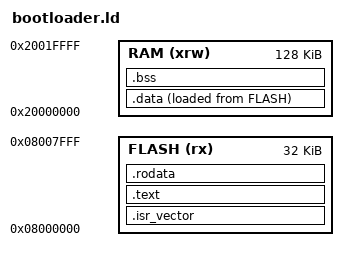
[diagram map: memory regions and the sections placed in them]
/* ============================================================================
 * Linker Script for STM32F446ZET6 Bootloader (BigTreeTech Octopus)
 * Sector 0 & 1: 32 KB (0x08000000 - 0x08007FFF)
 * ============================================================================ */

ENTRY(Reset_Handler)

_estack = ORIGIN(RAM) + LENGTH(RAM); /* 0x20020000 */

MEMORY
{
    FLASH (rx)  : ORIGIN = 0x08000000, LENGTH = 32K
    RAM   (xrw) : ORIGIN = 0x20000000, LENGTH = 128K
}

SECTIONS
{
    .isr_vector :
    {
        . = ALIGN(4);
        KEEP(*(.isr_vector))
        . = ALIGN(4);
    } > FLASH

    .text :
    {
        . = ALIGN(4);
        *(.text)
        *(.text*)
        *(.glue_7)
        *(.glue_7t)
        *(.eh_frame)
        . = ALIGN(4);
        _etext = .;
    } > FLASH

    .rodata :
    {
        . = ALIGN(4);
        *(.rodata)
        *(.rodata*)
        . = ALIGN(4);
    } > FLASH

    _sidata = LOADADDR(.data);

    .data :
    {
        . = ALIGN(4);
        _sdata = .;
        *(.data)
        *(.data*)
        . = ALIGN(4);
        _edata = .;
    } > RAM AT> FLASH

    .bss :
    {
        . = ALIGN(4);
        _sbss = .;
        *(.bss)
        *(.bss*)
        *(COMMON)
        . = ALIGN(4);
        _ebss = .;
    } > RAM

    /DISCARD/ :
    {
        libc.a ( * )
        libm.a ( * )
        libgcc.a ( * )
    }
}
